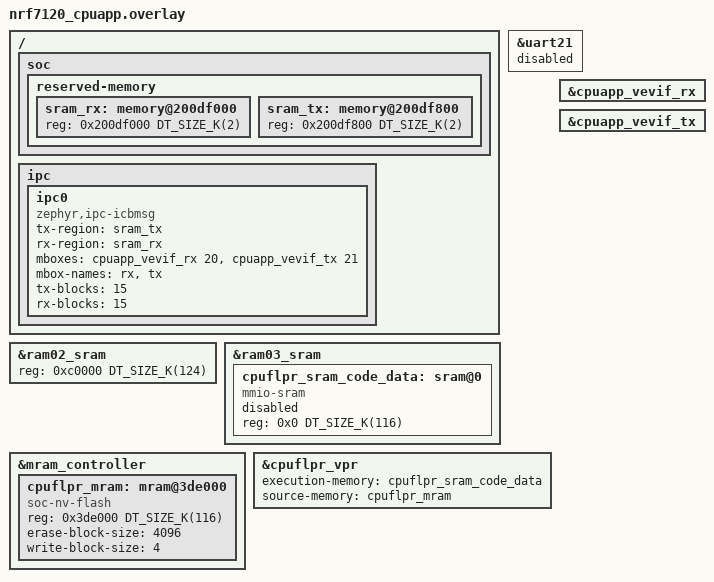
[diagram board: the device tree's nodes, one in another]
/*
 * Copyright (c) 2026 Nordic Semiconductor
 * SPDX-License-Identifier: Apache-2.0
 */

/ {
	soc {
		reserved-memory {
			#address-cells = <1>;
			#size-cells = <1>;

			sram_rx: memory@200df000 {
				reg = <0x200df000 DT_SIZE_K(2)>;
			};

			sram_tx: memory@200df800 {
				reg = <0x200df800 DT_SIZE_K(2)>;
			};
		};
	};

	ipc {
		ipc0: ipc0 {
			compatible = "zephyr,ipc-icbmsg";
			tx-region = <&sram_tx>;
			rx-region = <&sram_rx>;
			mboxes = <&cpuapp_vevif_rx 20>, <&cpuapp_vevif_tx 21>;
			mbox-names = "rx", "tx";
			tx-blocks = <15>;
			rx-blocks = <15>;
			status = "okay";
		};
	};
};

&ram02_sram {
	reg = <0xc0000 DT_SIZE_K(124)>;
	ranges = <0x0 0xc0000 DT_SIZE_K(124)>;
};

&ram03_sram {
	cpuflpr_sram_code_data: sram@0 {
		compatible = "mmio-sram";
		reg = <0x0 DT_SIZE_K(116)>;
		status = "reserved";
	};
};

&mram_controller {
	cpuflpr_mram: mram@3de000 {
		compatible = "soc-nv-flash";
		reg = <0x3de000 DT_SIZE_K(116)>;
		ranges = <0x0 0x3de000 DT_SIZE_K(116)>;
		erase-block-size = <4096>;
		write-block-size = <4>;
		#address-cells = <1>;
		#size-cells = <1>;
	};
};

&uart21 {
	status = "reserved";
};

&cpuflpr_vpr {
	execution-memory = <&cpuflpr_sram_code_data>;
	source-memory = <&cpuflpr_mram>;
};

&cpuapp_vevif_rx {
	status = "okay";
};

&cpuapp_vevif_tx {
	status = "okay";
};
